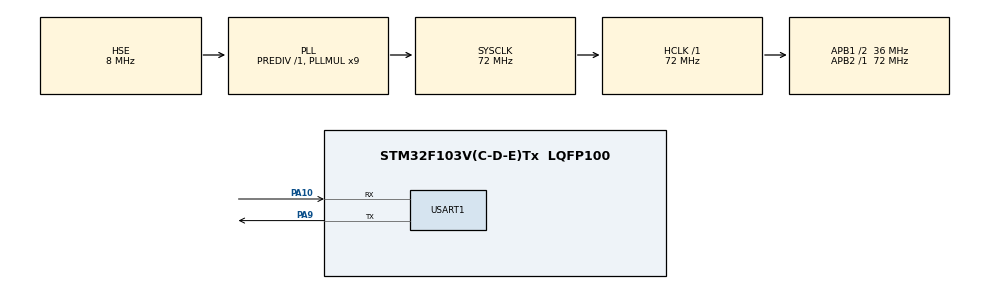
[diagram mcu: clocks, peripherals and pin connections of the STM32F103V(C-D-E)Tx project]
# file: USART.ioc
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Mcu.Family=STM32F1
Mcu.Name=STM32F103V(C-D-E)Tx
Mcu.Package=LQFP100
NVIC.PriorityGroup=NVIC_PRIORITYGROUP_4
NVIC.USART1_IRQn=true\:0\:0\:false\:false\:true\:true\:true\:true
OSC_IN.Mode=HSE-External-Oscillator
OSC_IN.Signal=RCC_OSC_IN
OSC_OUT.Mode=HSE-External-Oscillator
OSC_OUT.Signal=RCC_OSC_OUT
PA10.Mode=Asynchronous
PA10.Signal=USART1_RX
PA13.Mode=Serial_Wire
PA13.Signal=SYS_JTMS-SWDIO
PA14.Mode=Serial_Wire
PA14.Signal=SYS_JTCK-SWCLK
PA9.Mode=Asynchronous
PA9.Signal=USART1_TX
ProjectManager.HeapSize=0x200
ProjectManager.StackSize=0x400
ProjectManager.TargetToolchain=MDK-ARM V5.32
RCC.AHBFreq_Value=72000000
RCC.APB1CLKDivider=RCC_HCLK_DIV2
RCC.APB1Freq_Value=36000000
RCC.APB1TimFreq_Value=72000000
RCC.APB2Freq_Value=72000000
RCC.APB2TimFreq_Value=72000000
RCC.HCLKFreq_Value=72000000
RCC.PLLMUL=RCC_PLL_MUL9
RCC.PLLSourceVirtual=RCC_PLLSOURCE_HSE
RCC.SYSCLKFreq_VALUE=72000000
RCC.SYSCLKSource=RCC_SYSCLKSOURCE_PLLCLK
RCC.USBFreq_Value=72000000
USART1.VirtualMode=VM_ASYNC
board=custom

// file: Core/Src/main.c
/* USER CODE BEGIN Header */
/**
  ******************************************************************************
  * @file           : main.c
  * @brief          : Main program body
  ******************************************************************************
  * @attention
  *
  * Copyright (c) 2023 STMicroelectronics.
  * All rights reserved.
  *
  * This software is licensed under terms that can be found in the LICENSE file
  * in the root directory of this software component.
  * If no LICENSE file comes with this software, it is provided AS-IS.
  *
  ******************************************************************************
  */
/* USER CODE END Header */
#include "main.h"
#include "usart.h"
#include "gpio.h"

/* USER CODE BEGIN Includes */
#include <string.h>
#include <stdio.h>
#include "bsp_led.h"
#include "stm32f1xx.h"

/* USER CODE END Includes */

/* USER CODE BEGIN PTD */
__IO uint32_t CRCValue = 0;         //用于存放产生的CRC校验值
CRC_HandleTypeDef crc;

/* USER CODE END PTD */

void SystemClock_Config(void);
/* USER CODE BEGIN PFP */
void CRC_Init(void);
/* USER CODE END PFP */

int main(void)
{
  /* USER CODE BEGIN 1 */
	uint8_t i = 0;
  /* USER CODE END 1 */

  /* MCU Configuration--------------------------------------------------------*/

  /* Reset of all peripherals, Initializes the Flash interface and the Systick. */
  HAL_Init();

  /* USER CODE BEGIN Init */
	CRC_Init();

  /* USER CODE END Init */

  /* Configure the system clock */
  SystemClock_Config();

  /* Initialize all configured peripherals */
  MX_GPIO_Init();
  MX_USART1_UART_Init();
  /* USER CODE BEGIN 2 */

	for(i=0;i<BUFFER_SIZE;i++)
	{
		//对该寄存器进行写操作时，作为输入寄存器，可以输入要进行CRC计算的新数据。
		//对该寄存器进行读操作时，返回上一次CRC计算的结果。
		//每一次写入数据寄存器，其计算结果是前一次CRC计算结果和新计算结果的组合(对整个32位字
		//进行CRC计算，而不是逐字节地计算)。
		CRCValue = HAL_CRC_Accumulate(&crc,(uint32_t *)DataBuffer,BUFFER_SIZE);
		printf("\r\n 32-bit CRC 校验码为：0x%x \r\n",CRCValue);
	}
	printf("\r\n CRC（循环冗余校验）测试成功 \r\n");

	for(;;)
	{

	}
  /* USER CODE END 2 */

  /* Infinite loop */
  while (1)
  {

  }
}

void SystemClock_Config(void)
{
  RCC_OscInitTypeDef RCC_OscInitStruct = {0};
  RCC_ClkInitTypeDef RCC_ClkInitStruct = {0};

  /** Initializes the RCC Oscillators according to the specified parameters
  * in the RCC_OscInitTypeDef structure.
  */
  RCC_OscInitStruct.OscillatorType = RCC_OSCILLATORTYPE_HSE;
  RCC_OscInitStruct.HSEState = RCC_HSE_ON;
  RCC_OscInitStruct.HSEPredivValue = RCC_HSE_PREDIV_DIV1;
  RCC_OscInitStruct.HSIState = RCC_HSI_ON;
  RCC_OscInitStruct.PLL.PLLState = RCC_PLL_ON;
  RCC_OscInitStruct.PLL.PLLSource = RCC_PLLSOURCE_HSE;
  RCC_OscInitStruct.PLL.PLLMUL = RCC_PLL_MUL9;
  if (HAL_RCC_OscConfig(&RCC_OscInitStruct) != HAL_OK)
  {
    Error_Handler();
  }

  /** Initializes the CPU, AHB and APB buses clocks
  */
  RCC_ClkInitStruct.ClockType = RCC_CLOCKTYPE_HCLK|RCC_CLOCKTYPE_SYSCLK
                              |RCC_CLOCKTYPE_PCLK1|RCC_CLOCKTYPE_PCLK2;
  RCC_ClkInitStruct.SYSCLKSource = RCC_SYSCLKSOURCE_PLLCLK;
  RCC_ClkInitStruct.AHBCLKDivider = RCC_SYSCLK_DIV1;
  RCC_ClkInitStruct.APB1CLKDivider = RCC_HCLK_DIV2;
  RCC_ClkInitStruct.APB2CLKDivider = RCC_HCLK_DIV1;

  if (HAL_RCC_ClockConfig(&RCC_ClkInitStruct, FLASH_LATENCY_2) != HAL_OK)
  {
    Error_Handler();
  }
}

/* USER CODE BEGIN 4 */

void CRC_Init(void)
{
	/* 外设时钟使能 */
	__HAL_RCC_CRC_CLK_ENABLE();

	crc.Instance = CRC;
	HAL_CRC_Init(&crc);
}

void HAL_UART_RxCpltCallback(UART_HandleTypeDef *huart)
{
	if(huart->Instance == USART1)
	{
		/*例程演示从简，当一轮接收超过了RxBuff，继续使用同一个RxBuff接收，接收字节数仍然累计，接收内容从头覆盖。
		根据实际的项目编写多份Rxbuff，类似循环队列切换到另一个Buff和及时处理已接收部分，*/
    Rxlen += huart1.RxXferSize;
		HAL_UART_Receive_IT(&huart1,(uint8_t*)RxBuff,BUFFSIZE);
	}
}

/* USER CODE END 4 */

void Error_Handler(void)
{
  __disable_irq();
  while (1)
  {
  }
}
